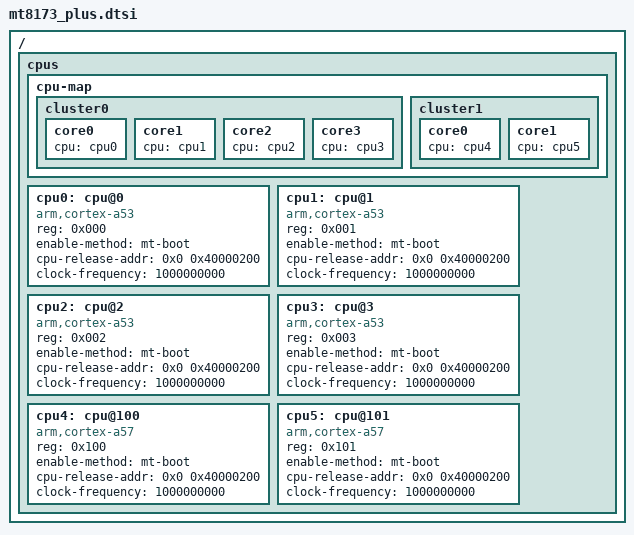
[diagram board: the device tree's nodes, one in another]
/*
 * Copyright (c) 2014 MediaTek Inc.
 * Author: Eddie Huang <eddie.huang@mediatek.com>
 *
 * This program is free software; you can redistribute it and/or modify
 * it under the terms of the GNU General Public License version 2 as
 * published by the Free Software Foundation.
 *
 * This program is distributed in the hope that it will be useful,
 * but WITHOUT ANY WARRANTY; without even the implied warranty of
 * MERCHANTABILITY or FITNESS FOR A PARTICULAR PURPOSE.  See the
 * GNU General Public License for more details.
 */

#include "mt8173.dtsi"

/ {
	cpus {
		#address-cells = <1>;
		#size-cells = <0>;

		cpu-map {
			cluster0 {
				core0 {
					cpu = <&cpu0>;
				};
				core1 {
					cpu = <&cpu1>;
				};
				core2 {
					cpu = <&cpu2>;
				};
				core3 {
					cpu = <&cpu3>;
				};
			};

			cluster1 {
				core0 {
					cpu = <&cpu4>;
				};
				core1 {
					cpu = <&cpu5>;
				};
			};
		};

		cpu0: cpu@0 {
			device_type = "cpu";
			compatible = "arm,cortex-a53";
			reg = <0x000>;
			enable-method = "mt-boot";
			cpu-release-addr = <0x0 0x40000200>;
			clock-frequency = <1000000000>;
		};

		cpu1: cpu@1 {
			device_type = "cpu";
			compatible = "arm,cortex-a53";
			reg = <0x001>;
			enable-method = "mt-boot";
			cpu-release-addr = <0x0 0x40000200>;
			clock-frequency = <1000000000>;
		};

		cpu2: cpu@2 {
			device_type = "cpu";
			compatible = "arm,cortex-a53";
			reg = <0x002>;
			enable-method = "mt-boot";
			cpu-release-addr = <0x0 0x40000200>;
			clock-frequency = <1000000000>;
		};

		cpu3: cpu@3 {
			device_type = "cpu";
			compatible = "arm,cortex-a53";
			reg = <0x003>;
			enable-method = "mt-boot";
			cpu-release-addr = <0x0 0x40000200>;
			clock-frequency = <1000000000>;
		};

		cpu4: cpu@100 {
			device_type = "cpu";
			compatible = "arm,cortex-a57";
			reg = <0x100>;
			enable-method = "mt-boot";
			cpu-release-addr = <0x0 0x40000200>;
			clock-frequency = <1000000000>;
		};

		cpu5: cpu@101 {
			device_type = "cpu";
			compatible = "arm,cortex-a57";
			reg = <0x101>;
			enable-method = "mt-boot";
			cpu-release-addr = <0x0 0x40000200>;
			clock-frequency = <1000000000>;
		};
	};
};

